VERSION ""

NS_ :

BS_:

BU_:

BO_ 2432614288 MODINSTRUM: 8 Vector__XXX
 SG_ Velocity : 0|16@1+ (1,0) [0|200] "km/h" Vector__XXX

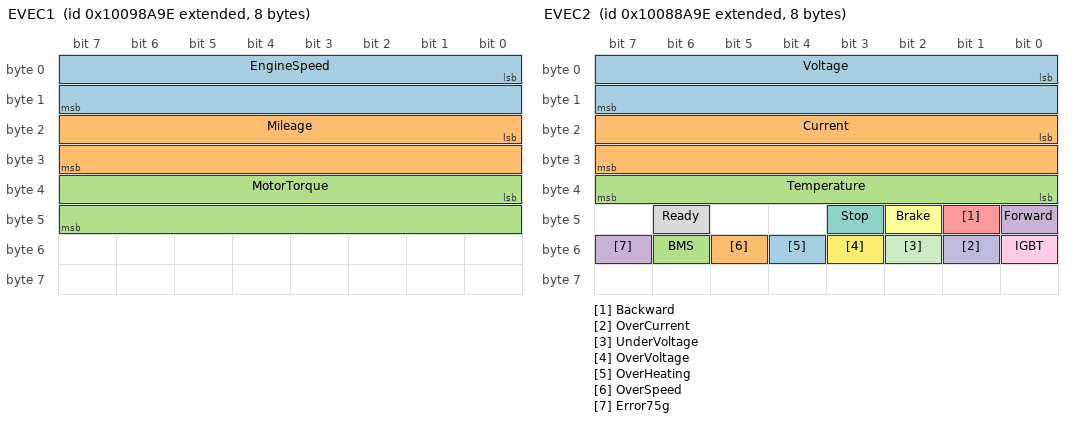
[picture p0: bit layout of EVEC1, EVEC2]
BO_ 2416544414 EVEC1: 8 Vector__XXX
 SG_ EngineSpeed : 0|16@1+ (1,0) [0|10000] "rpm" Vector__XXX
 SG_ Mileage     : 16|16@1+ (0.1,0) [0|300000] "km" Vector__XXX
 SG_ MotorTorque : 32|16@1+ (0.1,-1000) [-1000|1000] "Nm" Vector__XXX

BO_ 2416478878 EVEC2: 8 Vector__XXX
 SG_ Voltage : 0|16@1+ (0.1,-1000) [0|500] "v" Vector__XXX
 SG_ Current :16|16@1+ (0.1,-1000) [-500|500] "A" Vector__XXX
 SG_ Temperature :32|8@1+ (0.1,40) [0|100] "A" Vector__XXX
 SG_ Forward  :40|1@0+ (1,0) [0|0] "-" Vector__XXX
 SG_ Backward :41|1@0+ (1,0) [0|0] "-" Vector__XXX
 SG_ Brake    :42|1@0+ (1,0) [0|0] "-" Vector__XXX
 SG_ Stop     :43|1@0+ (1,0) [0|0] "-" Vector__XXX
 SG_ Ready    :46|1@0+ (1,0) [0|0] "-" Vector__XXX
 SG_ IGBT         :48|1@0+ (1,0) [0|0] "-" Vector__XXX
 SG_ OverCurrent  :49|1@0+ (1,0) [0|0] "-" Vector__XXX
 SG_ UnderVoltage :50|1@0+ (1,0) [0|0] "-" Vector__XXX
 SG_ OverVoltage  :51|1@0+ (1,0) [0|0] "-" Vector__XXX
 SG_ OverHeating  :52|1@0+ (1,0) [0|0] "-" Vector__XXX
 SG_ OverSpeed    :53|1@0+ (1,0) [0|0] "-" Vector__XXX
 SG_ BMS          :54|1@0+ (1,0) [0|0] "-" Vector__XXX
 SG_ Error75g     :55|1@0+ (1,0) [0|0] "-" Vector__XXX

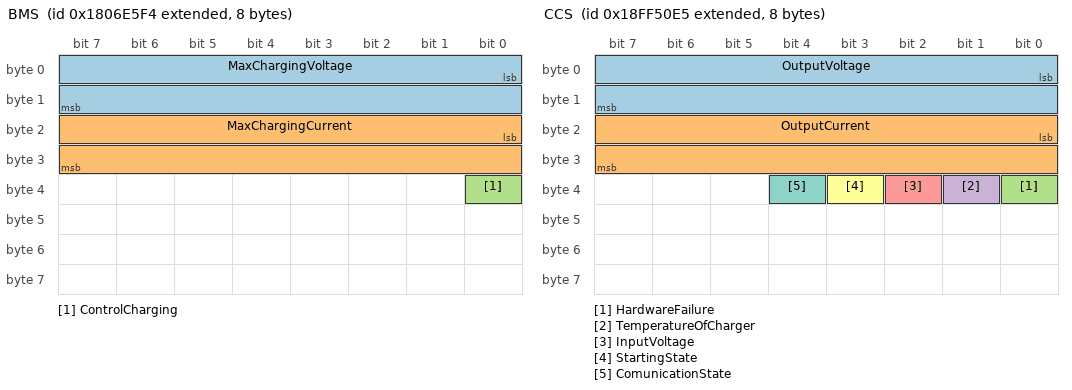
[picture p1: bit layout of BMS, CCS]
BO_ 2550588916 BMS: 8 Vector__XXX
 SG_ MaxChargingVoltage :  0|16@1+ (0.1,0) [0|1000] "V" Vector__XXX
 SG_ MaxChargingCurrent : 16|16@1+ (0.1,0) [0|1000] "A" Vector__XXX
 SG_ ControlCharging  : 32|1@0 + (1,0) [0|0] "-" Vector__XXX

BO_ 2566869221 CCS: 8 Vector__XXX
 SG_ OutputVoltage :    0|16@1+ (0.1,0) [0|10000] "V" Vector__XXX
 SG_ OutputCurrent :   16|16@1+ (0.1,0) [0|10000] "A" Vector__XXX
 SG_ HardwareFailure           : 32|1@0 + (1,0)   [0|0] "-" Vector__XXX
 SG_ TemperatureOfCharger : 33|1@0 + (1,0)   [0|0] "-" Vector__XXX
 SG_ InputVoltage        : 34|1@0 + (1,0)   [0|0] "-" Vector__XXX
 SG_ StartingState             : 35|1@0 + (1,0)   [0|0] "-" Vector__XXX
 SG_ ComunicationState  : 36|1@0 + (1,0)   [0|0] "-" Vector__XXX

CM_ BO_ 2432614288 "Modulo de instrumentacao";
CM_ SG_ 2432614288 Velocity "Velocidade da roda dianteira ";

CM_ BO_ 2416544414 "Electric Vehicle Electronic Engine Controller 1";
CM_ SG_ 2416544414 EngineSpeed "Atual rotacao do motor electrico.";
CM_ SG_ 2416544414 Mileage "Atual quilometragem. ";
CM_ SG_ 2416544414 MotorTorque "Atual torque do motor. ";

CM_ BO_ 2416478878 "Electric Vehicle Electronic Engine Controller 2";
CM_ SG_ 2416478878 Voltage "Voltage of motor controller. ";
CM_ SG_ 2416478878 Current "Current of motor controller. ";
CM_ SG_ 2416478878 Temperature "Temperature of motor controller. ";
CM_ SG_ 2416478878 Forward "Estado do motor para frente. ";
CM_ SG_ 2416478878 Backward "Estado do motor para traz. ";
CM_ SG_ 2416478878 Brake "Estado do motor Freio. ";
CM_ SG_ 2416478878 Stop "Estado do motor Parada. ";
CM_ SG_ 2416478878 Ready "Estado do motor Pronto. ";
CM_ SG_ 2416478878 IGBT "Erro no IGBT. ";
CM_ SG_ 2416478878 OverCurrent "Erro de Sobre Corrente Overcurrent. ";
CM_ SG_ 2416478878 UnderVoltage "Erro de Sob tensao Undervoltage. ";
CM_ SG_ 2416478878 OverVoltage "Erro de Sobre tensao OverVoltage. ";
CM_ SG_ 2416478878 OverHeating "Erro de Sobre Temperatura OverHeating. ";
CM_ SG_ 2416478878 OverSpeed "Erro de Sobre Velocidade OverSpeed. ";
CM_ SG_ 2416478878 BMS "Erro de BMS. ";
CM_ SG_ 2416478878 Error75g "Erro de 75 graus Celsius. ";

CM_ BO_ 2550588916 "Battery Management System";
CM_ SG_ 2550588916 MaxChargingVoltage "Tensao maxima admisivel ";
CM_ SG_ 2550588916 MaxChargingCurrent "Corrente maxima admisivel ";
CM_ SG_ 2550588916 ControlCharging "controle charging 0=start 1=stop ";

CM_ BO_ 2566869221 "Charger Controle System";
CM_ SG_ 2566869221 OutputVoltage "Tensao de saida. ";
CM_ SG_ 2566869221 OutputCurrent "Corrente de saida. ";
CM_ SG_ 2566869221 HardwareFailure  "0=normal 1=failure ";
CM_ SG_ 2566869221 TemperatureOfCharger  "0=normal 1=Over temperature protection";
CM_ SG_ 2566869221 InputVoltage  "0=normal ";
CM_ SG_ 2566869221 StartingState  "0=charger detects battery voltage and starts, 1=charges stays turned of (to prevent reverse polarity) ";
CM_ SG_ 2566869221 ComunicationState  "0=communication is normal, 1=communication recieve time-out ";

BA_DEF_ SG_  "SPN" INT 0 524287;
BA_DEF_ BO_  "VFrameFormat" ENUM  "StandardCAN","ExtendedCAN","reserved","J1939PG";
BA_DEF_  "DatabaseVersion" STRING ;
BA_DEF_  "BusType" STRING ;
BA_DEF_  "ProtocolType" STRING ;
BA_DEF_  "DatabaseCompiler" STRING ;
BA_DEF_DEF_  "SPN" 0;
BA_DEF_DEF_  "VFrameFormat" "J1939PG";
BA_DEF_DEF_  "DatabaseVersion" "";
BA_DEF_DEF_  "BusType" "";
BA_DEF_DEF_  "ProtocolType" "";
BA_DEF_DEF_  "DatabaseCompiler" "";
BA_ "ProtocolType" "J1939";
BA_ "BusType" "CAN";
BA_ "DatabaseCompiler" "Projeto BREletrico UnB";
BA_ "DatabaseVersion" "1.0.0";
BA_ "SPN" SG_ 2416544414 EngineSpeed 190;
BA_ "SPN" SG_ 2416478878 Voltage 84;
